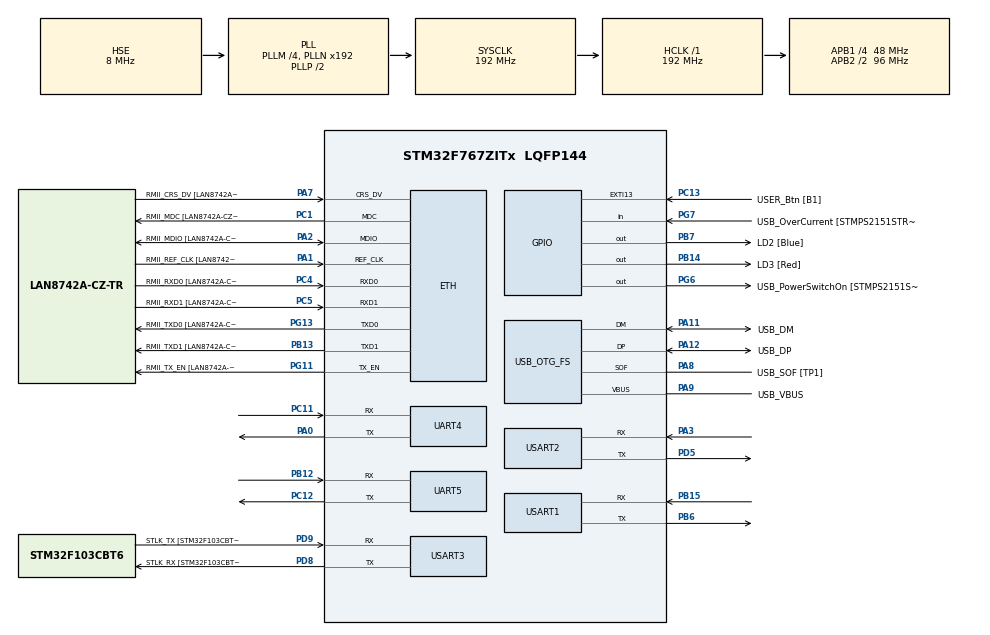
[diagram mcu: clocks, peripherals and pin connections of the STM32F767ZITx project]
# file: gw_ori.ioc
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ETH.MACAddr=AC\:80\:E1\:83\:05\:17
ETH.MediaInterface=ETH_MEDIA_INTERFACE_RMII
ETH.PHY_Name=LAN8742A_PHY_ADDRESS
ETH.PHY_Value=0
ETH.PhyAddress=0
FREERTOS.Queues01=modbus_task_q1,32,modbus_rtu_task_t,0,Dynamic,NULL,NULL;modbus_task_q2,32,modbus_rtu_task_t,0,Dynamic,NULL,NULL
FREERTOS.Tasks01=defaultTask,0,128,StartDefaultTask,Default,NULL,Dynamic,NULL,NULL;webserver,-3,512,start_webserver,As external,NULL,Dynamic,NULL,NULL;modebus_master,-3,256,start_modbus_master,As external,NULL,Dynamic,NULL,NULL;modbus_slave,-3,256,start_modbus_slave,As external,NULL,Dynamic,NULL,NULL
LWIP.DHCP_DEBUG=LWIP_DBG_ON
LWIP.LWIP_AUTOIP=1
LWIP.LWIP_DHCP_AUTOIP_COOP=1
LWIP.LWIP_HTTPD=1
LWIP.LWIP_HTTPD_CGI_SSI=1
LWIP.MEMP_NUM_TCP_PCB=8
LWIP.MEMP_NUM_UDP_PCB=8
LWIP.UDP_DEBUG=LWIP_DBG_ON
LWIP.Version=v2.0.3_Cube
MBEDTLS.MBEDTLS_HAVE_TIME=0
MBEDTLS.MBEDTLS_HAVE_TIME_DATE=0
MBEDTLS.MBEDTLS_SSL_SRV_C=0
Mcu.Family=STM32F7
Mcu.Name=STM32F767ZITx
Mcu.Package=LQFP144
NVIC.ETH_IRQn=true\:5\:0\:false\:false\:true\:true\:false
NVIC.PriorityGroup=NVIC_PRIORITYGROUP_4
NVIC.TIM1_UP_TIM10_IRQn=true\:0\:0\:false\:false\:true\:false\:false
NVIC.TimeBase=TIM1_UP_TIM10_IRQn
NVIC.TimeBaseIP=TIM1
PA0/WKUP.Mode=Asynchronous
PA0/WKUP.Signal=UART4_TX
PA1.GPIO_Label=RMII_REF_CLK [LAN8742A-CZ-TR_REFCLK0]
PA1.Mode=RMII
PA1.Signal=ETH_REF_CLK
PA10.GPIO_Label=USB_ID
PA10.Signal=USB_OTG_FS_ID
PA11.GPIO_Label=USB_DM
PA11.Mode=Device_Only
PA11.Signal=USB_OTG_FS_DM
PA12.GPIO_Label=USB_DP
PA12.Mode=Device_Only
PA12.Signal=USB_OTG_FS_DP
PA13.GPIO_Label=TMS
PA13.Mode=Trace_Asynchronous_SW
PA13.Signal=SYS_JTMS-SWDIO
PA14.GPIO_Label=TCK
PA14.Mode=Trace_Asynchronous_SW
PA14.Signal=SYS_JTCK-SWCLK
PA2.GPIO_Label=RMII_MDIO [LAN8742A-CZ-TR_MDIO]
PA2.Mode=RMII
PA2.Signal=ETH_MDIO
PA3.Mode=Asynchronous
PA3.Signal=USART2_RX
PA7.GPIO_Label=RMII_CRS_DV [LAN8742A-CZ-TR_CRS_DV]
PA7.Mode=RMII
PA7.Signal=ETH_CRS_DV
PA8.GPIO_Label=USB_SOF [TP1]
PA8.Mode=Activate_SOF_FS
PA8.Signal=USB_OTG_FS_SOF
PA9.GPIO_Label=USB_VBUS
PA9.Mode=Activate_VBUS
PA9.Signal=USB_OTG_FS_VBUS
PB12.Mode=Asynchronous
PB12.Signal=UART5_RX
PB13.GPIO_Label=RMII_TXD1 [LAN8742A-CZ-TR_TXD1]
PB13.Mode=RMII
PB13.Signal=ETH_TXD1
PB14.GPIO_Label=LD3 [Red]
PB14.Signal=GPIO_Output
PB15.Mode=Asynchronous
PB15.Signal=USART1_RX
PB3.GPIO_Label=SWO
PB3.Mode=Trace_Asynchronous_SW
PB3.Signal=SYS_JTDO-SWO
PB6.Mode=Asynchronous
PB6.Signal=USART1_TX
PB7.GPIO_Label=LD2 [Blue]
PB7.Signal=GPIO_Output
PC1.GPIO_Label=RMII_MDC [LAN8742A-CZ-TR_MDC]
PC1.Mode=RMII
PC1.Signal=ETH_MDC
PC11.Mode=Asynchronous
PC11.Signal=UART4_RX
PC12.Mode=Asynchronous
PC12.Signal=UART5_TX
PC13.GPIO_Label=USER_Btn [B1]
PC13.Signal=GPXTI13
PC14/OSC32_IN.Mode=LSE-External-Oscillator
PC14/OSC32_IN.Signal=RCC_OSC32_IN
PC15/OSC32_OUT.Mode=LSE-External-Oscillator
PC15/OSC32_OUT.Signal=RCC_OSC32_OUT
PC4.GPIO_Label=RMII_RXD0 [LAN8742A-CZ-TR_RXD0]
PC4.Mode=RMII
PC4.Signal=ETH_RXD0
PC5.GPIO_Label=RMII_RXD1 [LAN8742A-CZ-TR_RXD1]
PC5.Mode=RMII
PC5.Signal=ETH_RXD1
PD5.Mode=Asynchronous
PD5.Signal=USART2_TX
PD8.GPIO_Label=STLK_RX [STM32F103CBT6_PA3]
PD8.Mode=Asynchronous
PD8.Signal=USART3_TX
PD9.GPIO_Label=STLK_TX [STM32F103CBT6_PA2]
PD9.Mode=Asynchronous
PD9.Signal=USART3_RX
PG11.GPIO_Label=RMII_TX_EN [LAN8742A-CZ-TR_TXEN]
PG11.Mode=RMII
PG11.Signal=ETH_TX_EN
PG13.GPIO_Label=RMII_TXD0 [LAN8742A-CZ-TR_TXD0]
PG13.Mode=RMII
PG13.Signal=ETH_TXD0
PG6.GPIO_Label=USB_PowerSwitchOn [STMPS2151STR_EN]
PG6.Signal=GPIO_Output
PG7.GPIO_Label=USB_OverCurrent [STMPS2151STR_FAULT]
PG7.Signal=GPIO_Input
PH0/OSC_IN.GPIO_Label=MCO [STM32F103CBT6_PA8]
PH0/OSC_IN.Mode=HSE-External-Clock-Source
PH0/OSC_IN.Signal=RCC_OSC_IN
PH1/OSC_OUT.Mode=HSE-External-Clock-Source
PH1/OSC_OUT.Signal=RCC_OSC_OUT
ProjectManager.HeapSize=0x200
ProjectManager.StackSize=0x400
ProjectManager.TargetToolchain=MDK-ARM V5
RCC.48MHZClocksFreq_Value=24000000
RCC.AHBFreq_Value=192000000
RCC.APB1CLKDivider=RCC_HCLK_DIV4
RCC.APB1Freq_Value=48000000
RCC.APB1TimFreq_Value=96000000
RCC.APB2CLKDivider=RCC_HCLK_DIV2
RCC.APB2Freq_Value=96000000
RCC.APB2TimFreq_Value=192000000
RCC.CortexFreq_Value=192000000
RCC.HCLKFreq_Value=192000000
RCC.HSE_VALUE=8000000
RCC.HSI_VALUE=16000000
RCC.PLLM=4
RCC.PLLMUL=RCC_PLL_MUL9
RCC.PLLQ=8
RCC.PRESCALERUSB=RCC_USBCLKSOURCE_PLL_DIV1_5
RCC.SYSCLKFreq_VALUE=192000000
RCC.SYSCLKSource=RCC_SYSCLKSOURCE_PLLCLK
RCC.SYSCLKSourceVirtual=RCC_SYSCLKSOURCE_PLLCLK
RCC.USBFreq_Value=48000000
RCC.VCOOutputFreq_Value=384000000
USART1.VirtualMode-Asynchronous=VM_ASYNC
USART2.VirtualMode-Asynchronous=VM_ASYNC
USART3.VirtualMode-Asynchronous=VM_ASYNC
USB_OTG_FS.VirtualMode=Device_Only
VP_FREERTOS_VS_ENABLE.Mode=Enabled
VP_LWIP_VS_Enabled.Mode=Enabled
VP_MBEDTLS_VS_MBEDTLS.Mode=Enabled
VP_SYS_VS_tim1.Mode=TIM1
board=NUCLEO-F767ZI

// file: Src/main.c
/**
  ******************************************************************************
  * @file           : main.c
  * @brief          : Main program body
  ******************************************************************************
  * This notice applies to any and all portions of this file
  * that are not between comment pairs USER CODE BEGIN and
  * USER CODE END. Other portions of this file, whether
  * inserted by the user or by software development tools
  * are owned by their respective copyright owners.
  *
  * Copyright (c) 2018 STMicroelectronics International N.V.
  * All rights reserved.
  *
  * Redistribution and use in source and binary forms, with or without
  * modification, are permitted, provided that the following conditions are met:
  *
  * 1. Redistribution of source code must retain the above copyright notice,
  *    this list of conditions and the following disclaimer.
  * 2. Redistributions in binary form must reproduce the above copyright notice,
  *    this list of conditions and the following disclaimer in the documentation
  *    and/or other materials provided with the distribution.
  * 3. Neither the name of STMicroelectronics nor the names of other
  *    contributors to this software may be used to endorse or promote products
  *    derived from this software without specific written permission.
  * 4. This software, including modifications and/or derivative works of this
  *    software, must execute solely and exclusively on microcontroller or
  *    microprocessor devices manufactured by or for STMicroelectronics.
  * 5. Redistribution and use of this software other than as permitted under
  *    this license is void and will automatically terminate your rights under
  *    this license.
  *
  * THIS SOFTWARE IS PROVIDED BY STMICROELECTRONICS AND CONTRIBUTORS "AS IS"
  * AND ANY EXPRESS, IMPLIED OR STATUTORY WARRANTIES, INCLUDING, BUT NOT
  * LIMITED TO, THE IMPLIED WARRANTIES OF MERCHANTABILITY, FITNESS FOR A
  * PARTICULAR PURPOSE AND NON-INFRINGEMENT OF THIRD PARTY INTELLECTUAL PROPERTY
  * RIGHTS ARE DISCLAIMED TO THE FULLEST EXTENT PERMITTED BY LAW. IN NO EVENT
  * SHALL STMICROELECTRONICS OR CONTRIBUTORS BE LIABLE FOR ANY DIRECT, INDIRECT,
  * INCIDENTAL, SPECIAL, EXEMPLARY, OR CONSEQUENTIAL DAMAGES (INCLUDING, BUT NOT
  * LIMITED TO, PROCUREMENT OF SUBSTITUTE GOODS OR SERVICES; LOSS OF USE, DATA,
  * OR PROFITS; OR BUSINESS INTERRUPTION) HOWEVER CAUSED AND ON ANY THEORY OF
  * LIABILITY, WHETHER IN CONTRACT, STRICT LIABILITY, OR TORT (INCLUDING
  * NEGLIGENCE OR OTHERWISE) ARISING IN ANY WAY OUT OF THE USE OF THIS SOFTWARE,
  * EVEN IF ADVISED OF THE POSSIBILITY OF SUCH DAMAGE.
  *
  ******************************************************************************
  */
#include "main.h"
#include "stm32f7xx_hal.h"
#include "cmsis_os.h"
#include "mbedtls.h"

/* USER CODE BEGIN Includes */
#include "gateway.h"
/* USER CODE END Includes */

UART_HandleTypeDef huart4;
UART_HandleTypeDef huart5;
UART_HandleTypeDef huart1;
UART_HandleTypeDef huart2;
UART_HandleTypeDef huart3;

PCD_HandleTypeDef hpcd_USB_OTG_FS;

osThreadId defaultTaskHandle;
osThreadId webserverHandle;
osThreadId modebus_masterHandle;
osThreadId modbus_slaveHandle;
osMessageQId modbus_task_q1Handle;
osMessageQId modbus_task_q2Handle;

/* USER CODE BEGIN PV */
/* Private variables ---------------------------------------------------------*/

/* USER CODE END PV */

void SystemClock_Config(void);
static void MX_GPIO_Init(void);
static void MX_USART3_UART_Init(void);
static void MX_USB_OTG_FS_PCD_Init(void);
static void MX_USART1_UART_Init(void);
static void MX_USART2_UART_Init(void);
static void MX_UART4_Init(void);
static void MX_UART5_Init(void);
void StartDefaultTask(void const * argument);
extern void start_webserver(void const * argument);
extern void start_modbus_master(void const * argument);
extern void start_modbus_slave(void const * argument);

/* USER CODE BEGIN PFP */
/* Private function prototypes -----------------------------------------------*/

/* USER CODE END PFP */

int main(void)
{

  /* MCU Configuration----------------------------------------------------------*/

  /* Reset of all peripherals, Initializes the Flash interface and the Systick. */
  HAL_Init();

  /* Configure the system clock */
  SystemClock_Config();

  /* Initialize all configured peripherals */
  MX_GPIO_Init();
  MX_USART3_UART_Init();
  MX_USB_OTG_FS_PCD_Init();
  MX_USART1_UART_Init();
  MX_USART2_UART_Init();
  MX_UART4_Init();
  MX_UART5_Init();
  /* USER CODE BEGIN 2 */
	printf("program start...\n");
  /* USER CODE END 2 */

  /* Create the thread(s) */
  /* definition and creation of defaultTask */
  osThreadDef(defaultTask, StartDefaultTask, osPriorityNormal, 0, 128);
  defaultTaskHandle = osThreadCreate(osThread(defaultTask), NULL);

  /* definition and creation of webserver */
  osThreadDef(webserver, start_webserver, osPriorityIdle, 0, 512);
  webserverHandle = osThreadCreate(osThread(webserver), NULL);

  /* definition and creation of modebus_master */
  osThreadDef(modebus_master, start_modbus_master, osPriorityIdle, 0, 256);
  modebus_masterHandle = osThreadCreate(osThread(modebus_master), NULL);

  /* definition and creation of modbus_slave */
  osThreadDef(modbus_slave, start_modbus_slave, osPriorityIdle, 0, 256);
  modbus_slaveHandle = osThreadCreate(osThread(modbus_slave), NULL);

  /* Create the queue(s) */
  /* definition and creation of modbus_task_q1 */
  osMessageQDef(modbus_task_q1, 32, modbus_rtu_task_t);
  modbus_task_q1Handle = osMessageCreate(osMessageQ(modbus_task_q1), NULL);

  /* definition and creation of modbus_task_q2 */
  osMessageQDef(modbus_task_q2, 32, modbus_rtu_task_t);
  modbus_task_q2Handle = osMessageCreate(osMessageQ(modbus_task_q2), NULL);

  /* Start scheduler */
  osKernelStart();

  /* We should never get here as control is now taken by the scheduler */

  /* Infinite loop */
  while (1)
  {

  }

}

void SystemClock_Config(void)
{

  RCC_OscInitTypeDef RCC_OscInitStruct;
  RCC_ClkInitTypeDef RCC_ClkInitStruct;
  RCC_PeriphCLKInitTypeDef PeriphClkInitStruct;

    /**Configure the main internal regulator output voltage
    */
  __HAL_RCC_PWR_CLK_ENABLE();

  __HAL_PWR_VOLTAGESCALING_CONFIG(PWR_REGULATOR_VOLTAGE_SCALE1);

    /**Initializes the CPU, AHB and APB busses clocks
    */
  RCC_OscInitStruct.OscillatorType = RCC_OSCILLATORTYPE_HSE;
  RCC_OscInitStruct.HSEState = RCC_HSE_BYPASS;
  RCC_OscInitStruct.PLL.PLLState = RCC_PLL_ON;
  RCC_OscInitStruct.PLL.PLLSource = RCC_PLLSOURCE_HSE;
  RCC_OscInitStruct.PLL.PLLM = 4;
  RCC_OscInitStruct.PLL.PLLN = 192;
  RCC_OscInitStruct.PLL.PLLP = RCC_PLLP_DIV2;
  RCC_OscInitStruct.PLL.PLLQ = 8;
  if (HAL_RCC_OscConfig(&RCC_OscInitStruct) != HAL_OK)
  {
    _Error_Handler(__FILE__, __LINE__);
  }

    /**Activate the Over-Drive mode
    */
  if (HAL_PWREx_EnableOverDrive() != HAL_OK)
  {
    _Error_Handler(__FILE__, __LINE__);
  }

    /**Initializes the CPU, AHB and APB busses clocks
    */
  RCC_ClkInitStruct.ClockType = RCC_CLOCKTYPE_HCLK|RCC_CLOCKTYPE_SYSCLK
                              |RCC_CLOCKTYPE_PCLK1|RCC_CLOCKTYPE_PCLK2;
  RCC_ClkInitStruct.SYSCLKSource = RCC_SYSCLKSOURCE_PLLCLK;
  RCC_ClkInitStruct.AHBCLKDivider = RCC_SYSCLK_DIV1;
  RCC_ClkInitStruct.APB1CLKDivider = RCC_HCLK_DIV4;
  RCC_ClkInitStruct.APB2CLKDivider = RCC_HCLK_DIV2;

  if (HAL_RCC_ClockConfig(&RCC_ClkInitStruct, FLASH_LATENCY_6) != HAL_OK)
  {
    _Error_Handler(__FILE__, __LINE__);
  }

  PeriphClkInitStruct.PeriphClockSelection = RCC_PERIPHCLK_USART1|RCC_PERIPHCLK_USART2
                              |RCC_PERIPHCLK_USART3|RCC_PERIPHCLK_UART4
                              |RCC_PERIPHCLK_UART5|RCC_PERIPHCLK_CLK48;
  PeriphClkInitStruct.Usart1ClockSelection = RCC_USART1CLKSOURCE_PCLK2;
  PeriphClkInitStruct.Usart2ClockSelection = RCC_USART2CLKSOURCE_PCLK1;
  PeriphClkInitStruct.Usart3ClockSelection = RCC_USART3CLKSOURCE_PCLK1;
  PeriphClkInitStruct.Uart4ClockSelection = RCC_UART4CLKSOURCE_PCLK1;
  PeriphClkInitStruct.Uart5ClockSelection = RCC_UART5CLKSOURCE_PCLK1;
  PeriphClkInitStruct.Clk48ClockSelection = RCC_CLK48SOURCE_PLL;
  if (HAL_RCCEx_PeriphCLKConfig(&PeriphClkInitStruct) != HAL_OK)
  {
    _Error_Handler(__FILE__, __LINE__);
  }

    /**Configure the Systick interrupt time
    */
  HAL_SYSTICK_Config(HAL_RCC_GetHCLKFreq()/1000);

    /**Configure the Systick
    */
  HAL_SYSTICK_CLKSourceConfig(SYSTICK_CLKSOURCE_HCLK);

  /* SysTick_IRQn interrupt configuration */
  HAL_NVIC_SetPriority(SysTick_IRQn, 15, 0);
}

/* UART4 init function */
static void MX_UART4_Init(void)
{

  huart4.Instance = UART4;
  huart4.Init.BaudRate = 115200;
  huart4.Init.WordLength = UART_WORDLENGTH_7B;
  huart4.Init.StopBits = UART_STOPBITS_1;
  huart4.Init.Parity = UART_PARITY_NONE;
  huart4.Init.Mode = UART_MODE_TX_RX;
  huart4.Init.HwFlowCtl = UART_HWCONTROL_NONE;
  huart4.Init.OverSampling = UART_OVERSAMPLING_16;
  huart4.Init.OneBitSampling = UART_ONE_BIT_SAMPLE_DISABLE;
  huart4.AdvancedInit.AdvFeatureInit = UART_ADVFEATURE_NO_INIT;
  if (HAL_UART_Init(&huart4) != HAL_OK)
  {
    _Error_Handler(__FILE__, __LINE__);
  }

}

/* UART5 init function */
static void MX_UART5_Init(void)
{

  huart5.Instance = UART5;
  huart5.Init.BaudRate = 115200;
  huart5.Init.WordLength = UART_WORDLENGTH_7B;
  huart5.Init.StopBits = UART_STOPBITS_1;
  huart5.Init.Parity = UART_PARITY_NONE;
  huart5.Init.Mode = UART_MODE_TX_RX;
  huart5.Init.HwFlowCtl = UART_HWCONTROL_NONE;
  huart5.Init.OverSampling = UART_OVERSAMPLING_16;
  huart5.Init.OneBitSampling = UART_ONE_BIT_SAMPLE_DISABLE;
  huart5.AdvancedInit.AdvFeatureInit = UART_ADVFEATURE_NO_INIT;
  if (HAL_UART_Init(&huart5) != HAL_OK)
  {
    _Error_Handler(__FILE__, __LINE__);
  }

}

/* USART1 init function */
static void MX_USART1_UART_Init(void)
{

  huart1.Instance = USART1;
  huart1.Init.BaudRate = 115200;
  huart1.Init.WordLength = UART_WORDLENGTH_7B;
  huart1.Init.StopBits = UART_STOPBITS_1;
  huart1.Init.Parity = UART_PARITY_NONE;
  huart1.Init.Mode = UART_MODE_TX_RX;
  huart1.Init.HwFlowCtl = UART_HWCONTROL_NONE;
  huart1.Init.OverSampling = UART_OVERSAMPLING_16;
  huart1.Init.OneBitSampling = UART_ONE_BIT_SAMPLE_DISABLE;
  huart1.AdvancedInit.AdvFeatureInit = UART_ADVFEATURE_NO_INIT;
  if (HAL_UART_Init(&huart1) != HAL_OK)
  {
    _Error_Handler(__FILE__, __LINE__);
  }

}

/* USART2 init function */
static void MX_USART2_UART_Init(void)
{

  huart2.Instance = USART2;
  huart2.Init.BaudRate = 115200;
  huart2.Init.WordLength = UART_WORDLENGTH_7B;
  huart2.Init.StopBits = UART_STOPBITS_1;
  huart2.Init.Parity = UART_PARITY_NONE;
  huart2.Init.Mode = UART_MODE_TX_RX;
  huart2.Init.HwFlowCtl = UART_HWCONTROL_NONE;
  huart2.Init.OverSampling = UART_OVERSAMPLING_16;
  huart2.Init.OneBitSampling = UART_ONE_BIT_SAMPLE_DISABLE;
  huart2.AdvancedInit.AdvFeatureInit = UART_ADVFEATURE_NO_INIT;
  if (HAL_UART_Init(&huart2) != HAL_OK)
  {
    _Error_Handler(__FILE__, __LINE__);
  }

}

/* USART3 init function */
static void MX_USART3_UART_Init(void)
{

  huart3.Instance = USART3;
  huart3.Init.BaudRate = 115200;
  huart3.Init.WordLength = UART_WORDLENGTH_7B;
  huart3.Init.StopBits = UART_STOPBITS_1;
  huart3.Init.Parity = UART_PARITY_NONE;
  huart3.Init.Mode = UART_MODE_TX_RX;
  huart3.Init.HwFlowCtl = UART_HWCONTROL_NONE;
  huart3.Init.OverSampling = UART_OVERSAMPLING_16;
  huart3.Init.OneBitSampling = UART_ONE_BIT_SAMPLE_DISABLE;
  huart3.AdvancedInit.AdvFeatureInit = UART_ADVFEATURE_NO_INIT;
  if (HAL_UART_Init(&huart3) != HAL_OK)
  {
    _Error_Handler(__FILE__, __LINE__);
  }

}

/* USB_OTG_FS init function */
static void MX_USB_OTG_FS_PCD_Init(void)
{

  hpcd_USB_OTG_FS.Instance = USB_OTG_FS;
  hpcd_USB_OTG_FS.Init.dev_endpoints = 6;
  hpcd_USB_OTG_FS.Init.speed = PCD_SPEED_FULL;
  hpcd_USB_OTG_FS.Init.dma_enable = DISABLE;
  hpcd_USB_OTG_FS.Init.ep0_mps = DEP0CTL_MPS_64;
  hpcd_USB_OTG_FS.Init.phy_itface = PCD_PHY_EMBEDDED;
  hpcd_USB_OTG_FS.Init.Sof_enable = ENABLE;
  hpcd_USB_OTG_FS.Init.low_power_enable = DISABLE;
  hpcd_USB_OTG_FS.Init.lpm_enable = DISABLE;
  hpcd_USB_OTG_FS.Init.vbus_sensing_enable = ENABLE;
  hpcd_USB_OTG_FS.Init.use_dedicated_ep1 = DISABLE;
  if (HAL_PCD_Init(&hpcd_USB_OTG_FS) != HAL_OK)
  {
    _Error_Handler(__FILE__, __LINE__);
  }

}

/** Configure pins as
        * Analog
        * Input
        * Output
        * EVENT_OUT
        * EXTI
*/
static void MX_GPIO_Init(void)
{

  GPIO_InitTypeDef GPIO_InitStruct;

  /* GPIO Ports Clock Enable */
  __HAL_RCC_GPIOC_CLK_ENABLE();
  __HAL_RCC_GPIOH_CLK_ENABLE();
  __HAL_RCC_GPIOA_CLK_ENABLE();
  __HAL_RCC_GPIOB_CLK_ENABLE();
  __HAL_RCC_GPIOD_CLK_ENABLE();
  __HAL_RCC_GPIOG_CLK_ENABLE();

  /*Configure GPIO pin Output Level */
  HAL_GPIO_WritePin(GPIOB, LD3_Pin|LD2_Pin, GPIO_PIN_RESET);

  /*Configure GPIO pin Output Level */
  HAL_GPIO_WritePin(USB_PowerSwitchOn_GPIO_Port, USB_PowerSwitchOn_Pin, GPIO_PIN_RESET);

  /*Configure GPIO pin : USER_Btn_Pin */
  GPIO_InitStruct.Pin = USER_Btn_Pin;
  GPIO_InitStruct.Mode = GPIO_MODE_IT_RISING;
  GPIO_InitStruct.Pull = GPIO_NOPULL;
  HAL_GPIO_Init(USER_Btn_GPIO_Port, &GPIO_InitStruct);

  /*Configure GPIO pins : LD3_Pin LD2_Pin */
  GPIO_InitStruct.Pin = LD3_Pin|LD2_Pin;
  GPIO_InitStruct.Mode = GPIO_MODE_OUTPUT_PP;
  GPIO_InitStruct.Pull = GPIO_NOPULL;
  GPIO_InitStruct.Speed = GPIO_SPEED_FREQ_LOW;
  HAL_GPIO_Init(GPIOB, &GPIO_InitStruct);

  /*Configure GPIO pin : USB_PowerSwitchOn_Pin */
  GPIO_InitStruct.Pin = USB_PowerSwitchOn_Pin;
  GPIO_InitStruct.Mode = GPIO_MODE_OUTPUT_PP;
  GPIO_InitStruct.Pull = GPIO_NOPULL;
  GPIO_InitStruct.Speed = GPIO_SPEED_FREQ_LOW;
  HAL_GPIO_Init(USB_PowerSwitchOn_GPIO_Port, &GPIO_InitStruct);

  /*Configure GPIO pin : USB_OverCurrent_Pin */
  GPIO_InitStruct.Pin = USB_OverCurrent_Pin;
  GPIO_InitStruct.Mode = GPIO_MODE_INPUT;
  GPIO_InitStruct.Pull = GPIO_NOPULL;
  HAL_GPIO_Init(USB_OverCurrent_GPIO_Port, &GPIO_InitStruct);

}

/* StartDefaultTask function */
void StartDefaultTask(void const * argument)
{
  /* MX_LWIP_Init() is generated within mbedtls_net_init() function in net_cockets.c file */
  /* Up to user to call mbedtls_net_init() function in MBEDTLS initialization step */

  /* Up to user define the empty MX_MBEDTLS_Init() function located in mbedtls.c file */
  MX_MBEDTLS_Init();

  for(;;)
  {
    osDelay(1);
  }
}

void HAL_TIM_PeriodElapsedCallback(TIM_HandleTypeDef *htim)
{
  if (htim->Instance == TIM1) {
    HAL_IncTick();
  }
}

void _Error_Handler(char *file, int line)
{
  while(1)
  {
  }
}

/************************ (C) COPYRIGHT STMicroelectronics *****END OF FILE****/
